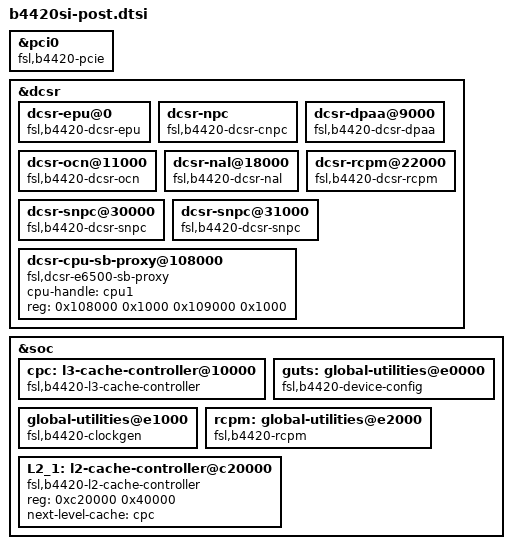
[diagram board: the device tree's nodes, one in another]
/include/ "b4si-post.dtsi"
&pci0 {
	compatible = "fsl,b4420-pcie", "fsl,qoriq-pcie-v2.4";
};
&dcsr {
	dcsr-epu@0 {
		compatible = "fsl,b4420-dcsr-epu", "fsl,dcsr-epu";
	};
	dcsr-npc {
		compatible = "fsl,b4420-dcsr-cnpc", "fsl,dcsr-cnpc";
	};
	dcsr-dpaa@9000 {
		compatible = "fsl,b4420-dcsr-dpaa", "fsl,dcsr-dpaa";
	};
	dcsr-ocn@11000 {
		compatible = "fsl,b4420-dcsr-ocn", "fsl,dcsr-ocn";
	};
	dcsr-nal@18000 {
		compatible = "fsl,b4420-dcsr-nal", "fsl,dcsr-nal";
	};
	dcsr-rcpm@22000 {
		compatible = "fsl,b4420-dcsr-rcpm", "fsl,dcsr-rcpm";
	};
	dcsr-snpc@30000 {
		compatible = "fsl,b4420-dcsr-snpc", "fsl,dcsr-snpc";
	};
	dcsr-snpc@31000 {
		compatible = "fsl,b4420-dcsr-snpc", "fsl,dcsr-snpc";
	};
	dcsr-cpu-sb-proxy@108000 {
		compatible = "fsl,dcsr-e6500-sb-proxy", "fsl,dcsr-cpu-sb-proxy";
		cpu-handle = <&cpu1>;
		reg = <0x108000 0x1000 0x109000 0x1000>;
	};
};
&soc {
	cpc: l3-cache-controller@10000 {
		compatible = "fsl,b4420-l3-cache-controller", "cache";
	};
	guts: global-utilities@e0000 {
		compatible = "fsl,b4420-device-config", "fsl,qoriq-device-config-2.0";
	};
	global-utilities@e1000 {
		compatible = "fsl,b4420-clockgen", "fsl,b4-clockgen",
			      "fsl,qoriq-clockgen-2.0";
	};
	rcpm: global-utilities@e2000 {
		compatible = "fsl,b4420-rcpm", "fsl,qoriq-rcpm-2.0";
	};
	L2_1: l2-cache-controller@c20000 {
		compatible = "fsl,b4420-l2-cache-controller";
		reg = <0xc20000 0x40000>;
		next-level-cache = <&cpc>;
	};
};
